# STM32H523 register map
File version: 1.3
CPU: CM33 r0p0, little endian, MPU, FPU, 4 interrupt priority bits
Registers are 32-bit, read-write, reset 0x0 unless marked. A register's access mark holds for its fields unless they carry their own. Offsets are from the block's base; [hi:lo] are bit positions; {n}, {i} and the like mark numbered series; 'fields as' and 'values as' point back to an identical list.

## SBS — SBS address block description
Base 0x44000400
Same registers: SBS_S 0x54000400
0x10 HDPLCR reset 0xB4 — SBS temporal isolation control register
  [7:0] INCR_HDPL — increment HDPL value
0x14 HDPLSR ro reset not defined — SBS temporal isolation status register
  [7:0] HDPL — temporal isolation level
0x18 NEXTHDPLCR — SBS next HDPL control register
  [1:0] NEXTHDPL — index to point to a higher HDPL than the current one
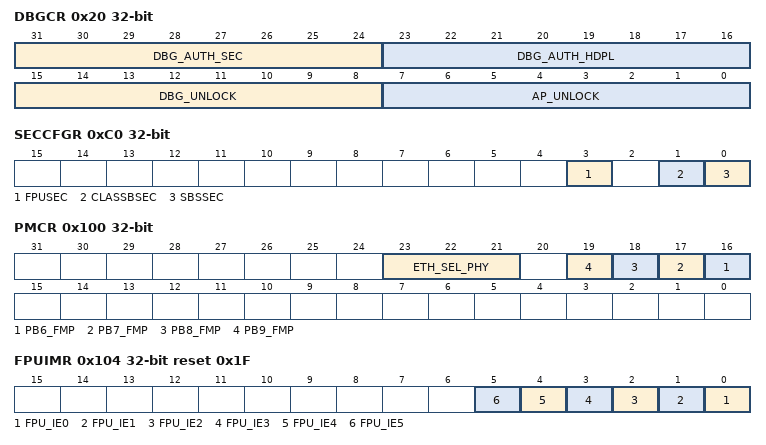
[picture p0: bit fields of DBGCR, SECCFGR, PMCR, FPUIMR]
0x20 DBGCR — SBS debug control register
  [31:24] DBG_AUTH_SEC — control debug opening secure/non-secure
  [23:16] DBG_AUTH_HDPL — authenticated debug temporal isolation level
  [15:8] DBG_UNLOCK — debug unlock when DBG_AUTH_HDPL is reached
  [7:0] AP_UNLOCK — access port unlock
0x24 DBGLOCKR reset 0xB4 — SBS debug lock register
  [7:0] DBGCFG_LOCK — debug configuration lock
0x34 RSSCMDR — SBS RSS command register
  [15:0] RSSCMD — RSS command
0xA0 EPOCHSELCR — SBS EPOCH selection control register
  [1:0] EPOCH_SEL — select EPOCH value to be sent to the SAES
0xC0 SECCFGR — SBS security mode configuration control register
  [3] FPUSEC — FPU security enable
  [1] CLASSBSEC — ClassB security enable
  [0] SBSSEC — SBS clock control, memory-erase status register and compensation cell register security enable
0x100 PMCR — SBS product mode and configuration register
  [23:21] ETH_SEL_PHY — Ethernet PHY interface selection
  [n+10] PB{n}_FMP (n=6..9) — Fast-mode Plus driving capability activation on PB{n}
0x104 FPUIMR reset 0x1F — SBS FPU interrupt mask register
  [n] FPU_IE{n} (n=0..5) — FPU interrupt enable
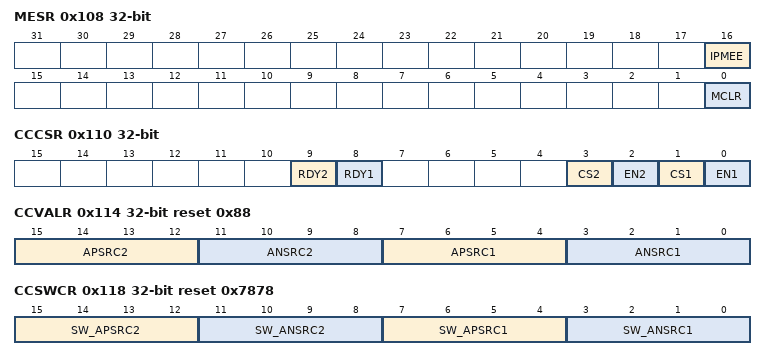
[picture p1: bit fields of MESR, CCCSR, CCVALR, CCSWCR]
0x108 MESR (reset mask 0xFFFFFFF0) — SBS memory erase status register
  [16] IPMEE — ICACHE erase status
  [0] MCLR — device memories erase status
0x110 CCCSR — SBS compensation cell for I/Os control and status register
  [9] RDY2 ro — VDDIO2 compensation cell ready flag
  [8] RDY1 ro — VDDIO compensation cell ready flag
  [3] CS2 — code selection for VDDIO2 power rail (reset value set to 1)
  [2] EN2 — enable compensation cell for VDDIO2 power rail
  [1] CS1 — code selection for VDDIO power rail (reset value set to 1)
  [0] EN1 — enable compensation cell for VDDIO power rail
0x114 CCVALR ro reset 0x88 — SBS compensation cell for I/Os value register
  [15:12] APSRC2 — compensation value for the PMOS transistor
  [11:8] ANSRC2 — Compensation value for the NMOS transistor
  [7:4] APSRC1 — compensation value for the PMOS transistor
  [3:0] ANSRC1 — compensation value for the NMOS transistor
0x118 CCSWCR reset 0x7878 — SBS compensation cell for I/Os software code register
  [15:12] SW_APSRC2 — PMOS compensation code for the Vless thansub>DDIOless than/sub> power rails
  [11:8] SW_ANSRC2 — NMOS compensation code for VDDIO power rails
  [7:4] SW_APSRC1 — PMOS compensation code for the VDD power rails
  [3:0] SW_ANSRC1 — NMOS compensation code for VDD power rails
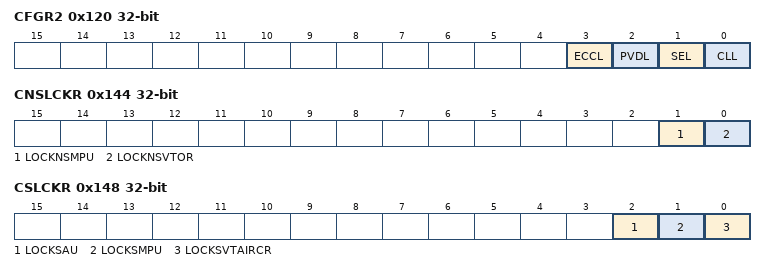
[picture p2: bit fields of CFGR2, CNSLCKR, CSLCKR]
0x120 CFGR2 — SBS Class B register
  [3] ECCL — ECC lock
  [2] PVDL — PVD lock
  [1] SEL — SRAM ECC error lock
  [0] CLL — core lockup lock
0x144 CNSLCKR — SBS CPU non-secure lock register
  [1] LOCKNSMPU — non-secure MPU register lock
  [0] LOCKNSVTOR — VTOR_NS register lock
0x148 CSLCKR — SBS CPU secure lock register
  [2] LOCKSAU — SAU registers lock
  [1] LOCKSMPU — secure MPU registers lock
  [0] LOCKSVTAIRCR — VTOR_S and AIRCR register lock
0x14C ECCNMIR — SBS flift ECC NMI mask register
  [0] ECCNMI_MASK_EN — NMI behavior setup when a double ECC error occurs on flitf data part

## TIM6 — TIM6 address block description
Base 0x40001000
Same registers: TIM7 0x40001400, TIM6_S 0x50001000, TIM7_S 0x50001400
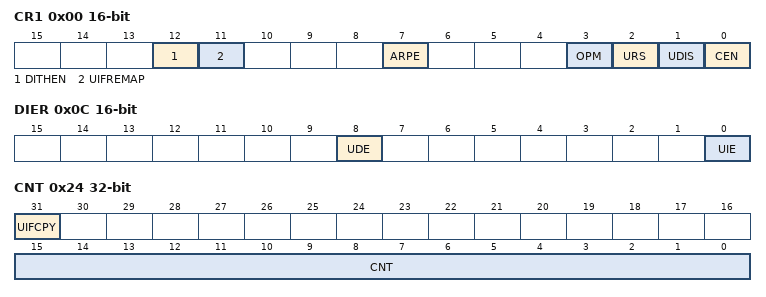
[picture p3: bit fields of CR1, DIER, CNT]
0x00 CR1 16-bit — TIM6 control register 1
  [12] DITHEN — Dithering enable
    0=Disabled (Dithering disabled); 1=Enabled (Dithering enabled)
  [11] UIFREMAP — UIF status bit remapping
    0=Disabled (No remapping. UIF status bit is not copied to TIMx_CNT register bit 31); 1=Enabled (Remapping enabled. UIF status bit is copied to TIMx_CNT register bit 31)
  [7] ARPE — Auto-reload preload enable
    0=Disabled (TIMx_APRR register is not buffered); 1=Enabled (TIMx_APRR register is buffered)
  [3] OPM — One-pulse mode
    0=Disabled (Counter is not stopped at update event); 1=Enabled (Counter stops counting at the next update event (clearing the CEN bit))
  [2] URS — Update request source
    0=AnyEvent (Any of counter overflow/underflow, setting UG, or update through slave mode, generates an update interrupt or DMA request); 1=CounterOnly (Only counter overflow/underflow generates an update interrupt or DMA request)
  [1] UDIS — Update disable
    0=Enabled (Update event enabled); 1=Disabled (Update event disabled)
  [0] CEN — Counter enable
    0=Disabled (Counter disabled); 1=Enabled (Counter enabled)
0x04 CR2 16-bit — TIM6 control register 2
  [6:4] MMS — Master mode selection
    0=Reset (Use UG bit from TIMx_EGR register); 1=Enable (Use CNT bit from TIMx_CEN register); 2=Update (Use the update event)
0x0C DIER 16-bit — TIM6 DMA/Interrupt enable register
  [8] UDE — Update DMA request enable
    0=Disabled (Update DMA request disabled); 1=Enabled (Update DMA request enabled)
  [0] UIE — Update interrupt enable
    0=Disabled (Update interrupt disabled); 1=Enabled (Update interrupt enabled)
0x10 SR 16-bit — TIM6 status register
  [0] UIF write-0-clears — Update interrupt flag
    on read: 0=NoUpdateOccurred; 1=UpdatePending (Update interrupt pending) | on write: 0=Clear flag
0x14 EGR 16-bit wo — TIM6 event generation register
  [0] UG — Update generation
    1=Update (Re-initializes the timer counter and generates an update of the registers.)
0x24 CNT — TIM6 counter
  [31] UIFCPY ro — UIF copy
    0=NoUpdateOccurred; 1=UpdatePending (Update interrupt pending)
  [15:0] CNT — Counter value
0x28 PSC 16-bit — TIM6 prescaler
  [15:0] PSC — Prescaler value
0x2C ARR reset 0xFFFF — TIM6 auto-reload register
  [19:0] ARR — Auto-reload value

## USBSRAM — USBSRAM address block description
Base 0x40016400
Same registers: USBSRAM_S 0x50016400
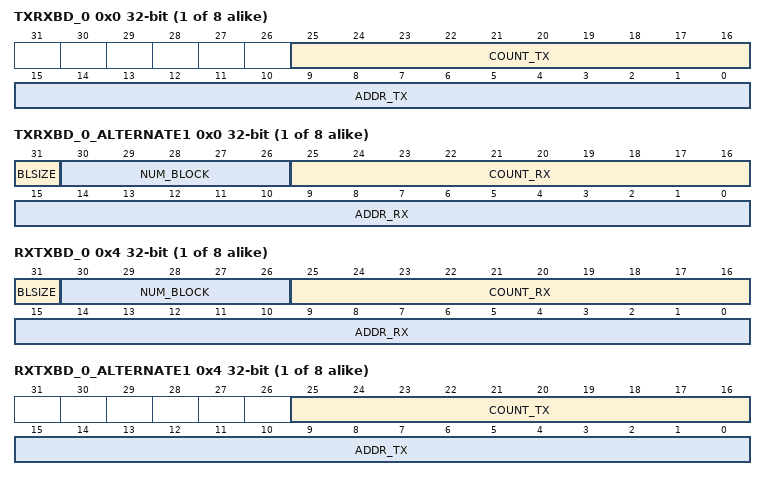
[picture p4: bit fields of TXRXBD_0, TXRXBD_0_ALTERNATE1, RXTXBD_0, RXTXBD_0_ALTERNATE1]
{0x0+8i} TXRXBD_{i} reset not defined (i=0..7) — Channel/endpoint transmit buffer descriptor {i}
  [25:16] COUNT_TX — Transmission byte count
  [15:0] ADDR_TX — Transmission buffer address
{0x0+8i} TXRXBD_{i}_ALTERNATE1 reset not defined (alternate view of TXRXBD_{i}) (i=0..7) — Channel/endpoint receive buffer descriptor {i}
  [31] BLSIZE — Block size
  [30:26] NUM_BLOCK — Number of blocks
  [25:16] COUNT_RX ro — Reception byte count
  [15:0] ADDR_RX — Reception buffer address
{0x4+8i} RXTXBD_{i} reset not defined (i=0..7) — Channel/endpoint receive buffer descriptor {i}
  fields as TXRXBD_0_ALTERNATE1
{0x4+8i} RXTXBD_{i}_ALTERNATE1 reset not defined (alternate view of RXTXBD_{i}) (i=0..7) — Channel/endpoint transmit buffer descriptor {i}
  fields as TXRXBD_0

## VREFBUF — VREFBUF address block description
Base 0x44007400
Same registers: VREFBUF_S 0x54007400
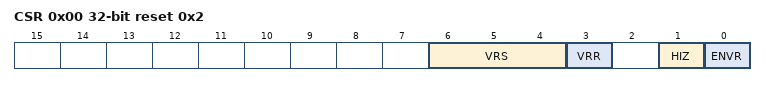
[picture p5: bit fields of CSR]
0x00 CSR reset 0x2 — VREFBUF control and status register
  [6:4] VRS — Voltage reference scale
  [3] VRR ro — Voltage reference buffer ready
  [1] HIZ — High impedance mode
  [0] ENVR — Voltage reference buffer mode enable
0x04 CCR (reset mask 0xFFFFFF00) — VREFBUF calibration control register
  [5:0] TRIM — Trimming code

## WWDG — WWDG address block description
Base 0x40002C00
Same registers: WWDG_S 0x50002C00
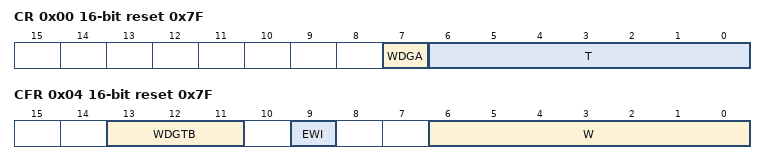
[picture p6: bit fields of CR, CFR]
0x00 CR 16-bit reset 0x7F — WWDG control register
  [7] WDGA — Activation bit
    0=Disabled (Watchdog disabled); 1=Enabled (Watchdog enabled)
  [6:0] T — 7-bit counter (MSB to LSB)
0x04 CFR 16-bit reset 0x7F — WWDG configuration register
  [13:11] WDGTB — Timer base
    0=Div1 (Counter clock (PCLK1 div 4096) div 1); 1=Div2 (Counter clock (PCLK1 div 4096) div 2); 2=Div4 (Counter clock (PCLK1 div 4096) div 4); 3=Div8 (Counter clock (PCLK1 div 4096) div 8); 4=Div16 (Counter clock (PCLK1 div 4096) div 16); 5=Div32 (Counter clock (PCLK1 div 4096) div 32); 6=Div64 (Counter clock (PCLK1 div 4096) div 64); 7=Div128 (Counter clock (PCLK1 div 4096) div 128)
  [9] EWI — Early wake-up interrupt enable
    on write: 1=Enable (interrupt occurs whenever the counter reaches the value 0x40)
  [6:0] W — 7-bit window value
0x08 SR 16-bit — WWDG status register
  [0] EWIF write-0-clears — Early wake-up interrupt flag
    on read: 0=Finished (The EWI Interrupt Service Routine has been serviced); 1=Pending (The EWI Interrupt Service Routine has been triggered) | on write: 0=Finished (The EWI Interrupt Service Routine has been serviced)
